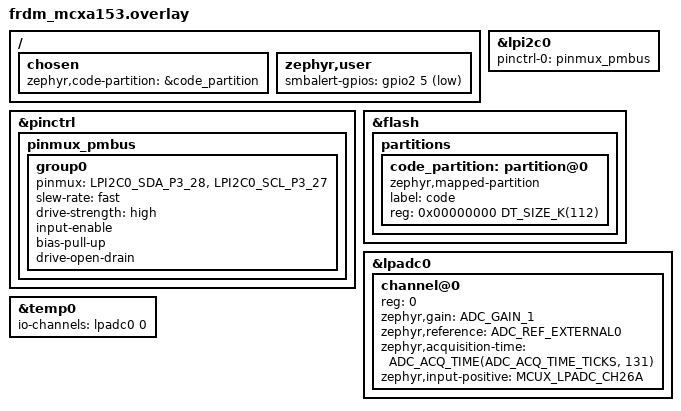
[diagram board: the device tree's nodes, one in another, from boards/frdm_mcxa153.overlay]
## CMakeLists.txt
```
# SPDX-License-Identifier: Apache-2.0
cmake_minimum_required(VERSION 3.20.0)

find_package(Zephyr REQUIRED HINTS $ENV{ZEPHYR_BASE})
project(pmbus_target)

set(PMBUS_LIB ${CMAKE_CURRENT_SOURCE_DIR}/../lib/pmbus)

target_include_directories(app PRIVATE ${PMBUS_LIB}/include)
target_sources(app PRIVATE
  ${PMBUS_LIB}/src/device.c
  ${PMBUS_LIB}/src/format.c
  ${PMBUS_LIB}/src/target.c
  src/main.c
  src/pmbus_i2c.c
  src/storage.c
  src/shell_cmds.c
)
```

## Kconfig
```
# SPDX-License-Identifier: Apache-2.0

mainmenu "FRDM-MCXA153 PMBus target"

config PMBUS_ADDRESS
	hex "PMBus target address (7-bit)"
	default 0x58
	range 0x08 0x77
	help
	  0x58 is the usual first PMBus address of a power supply; its FRU EEPROM would
	  sit at 0x50.

config PMBUS_UPDATE_PERIOD_MS
	int "Sensor and limit evaluation period (ms)"
	default 200

config PMBUS_SMBUS_TIMEOUT_MS
	int "SMBus target timeout (ms)"
	default 30
	help
	  If a transaction makes no progress for this long, the target interface resets
	  and the transaction is dropped. SMBus requires devices to reset between 25 ms
	  and 35 ms of SCL held low.

source "Kconfig.zephyr"
```

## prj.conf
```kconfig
# The PMBus target on LPI2C0.
CONFIG_I2C=y
CONFIG_I2C_TARGET=y

# Sensors: the P3T1755 on I3C0 and the die temperature through the ADC.
CONFIG_SENSOR=y
CONFIG_I3C=y
CONFIG_ADC=y

CONFIG_GPIO=y
CONFIG_HWINFO=y

# STORE_DEFAULT_ALL writes to the storage partition.
CONFIG_FLASH=y
CONFIG_FLASH_MAP=y
CONFIG_CRC=y

CONFIG_SHELL=y
CONFIG_LOG=y
CONFIG_LOG_MODE_MINIMAL=y
CONFIG_MAIN_STACK_SIZE=1536
```

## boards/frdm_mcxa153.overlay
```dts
/*
 * FRDM-MCXA153 as a PMBus target.
 *
 * SPDX-License-Identifier: Apache-2.0
 */

#include <zephyr/dt-bindings/adc/adc.h>
#include <zephyr/dt-bindings/adc/mcux-lpadc.h>
#include <zephyr/dt-bindings/gpio/gpio.h>

/ {
	chosen {
		zephyr,code-partition = &code_partition;
	};

	zephyr,user {
		/* SMBALERT#, open drain, on the mikroBUS INT pin (P2_5). */
		smbalert-gpios = <&gpio2 5 (GPIO_ACTIVE_LOW | GPIO_OPEN_DRAIN)>;
	};
};

/*
 * The PMBus pins: LPI2C0 on P3_27 (SCL) and P3_28 (SDA), the mikroBUS header J5 pins
 * 5 and 6. They are the only 5 V tolerant pins on the MCX A153, and the same pins
 * frdm-mcxa153-usb-i2c-hub uses, so two boards wire header to header.
 */
&pinctrl {
	pinmux_pmbus: pinmux_pmbus {
		group0 {
			pinmux = <LPI2C0_SDA_P3_28>,
				 <LPI2C0_SCL_P3_27>;
			slew-rate = "fast";
			drive-strength = "high";
			input-enable;
			bias-pull-up;
			drive-open-drain;
		};
	};
};

&lpi2c0 {
	pinctrl-0 = <&pinmux_pmbus>;
};

/* The board reserves the flash for MCUboot; this app runs without it. */
/delete-node/ &boot_partition;
/delete-node/ &slot0_partition;
/delete-node/ &slot1_partition;

&flash {
	partitions {
		code_partition: partition@0 {
			compatible = "zephyr,mapped-partition";
			label = "code";
			reg = <0x00000000 DT_SIZE_K(112)>;
		};
	};
};

/* The die temperature sensor, as samples/sensor/die_temp_polling sets it up. */
&lpadc0 {
	status = "okay";
	#address-cells = <1>;
	#size-cells = <0>;

	channel@0 {
		reg = <0>;
		zephyr,gain = "ADC_GAIN_1";
		zephyr,reference = "ADC_REF_EXTERNAL0";
		zephyr,acquisition-time = <ADC_ACQ_TIME(ADC_ACQ_TIME_TICKS, 131)>;
		zephyr,input-positive = <MCUX_LPADC_CH26A>;
	};
};

&temp0 {
	status = "okay";
	io-channels = <&lpadc0 0>;
};
```

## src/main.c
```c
/*
 * FRDM-MCXA153 PMBus target: a simulated 54 V to 12 V converter at
 * CONFIG_PMBUS_ADDRESS on LPI2C0, with its temperatures read from the on-board P3T1755
 * (READ_TEMPERATURE_1) and the MCU die (READ_TEMPERATURE_2).
 *
 * LEDs: green while the output is on and no status bit is set, red while any status
 * bit is set, blue on PMBus traffic.
 *
 * SPDX-License-Identifier: Apache-2.0
 */

#include <stdio.h>

#include <zephyr/device.h>
#include <zephyr/drivers/gpio.h>
#include <zephyr/drivers/hwinfo.h>
#include <zephyr/drivers/sensor.h>
#include <zephyr/kernel.h>
#include <zephyr/logging/log.h>

#include <pmbus/pmbus.h>

#include "app.h"

LOG_MODULE_REGISTER(main, LOG_LEVEL_INF);

struct pmbus_device pmbus_dev;
struct temp_override temp_override[2];

static const struct device *const temp_dev[2] = {
	DEVICE_DT_GET_OR_NULL(DT_ALIAS(ambient_temp0)),
	DEVICE_DT_GET_OR_NULL(DT_ALIAS(die_temp0)),
};
static const enum sensor_channel temp_chan[2] = {
	SENSOR_CHAN_AMBIENT_TEMP,
	SENSOR_CHAN_DIE_TEMP,
};

static const struct gpio_dt_spec led_green = GPIO_DT_SPEC_GET(DT_NODELABEL(green_led), gpios);
static const struct gpio_dt_spec led_red = GPIO_DT_SPEC_GET(DT_NODELABEL(red_led), gpios);
static const struct gpio_dt_spec led_blue = GPIO_DT_SPEC_GET(DT_NODELABEL(blue_led), gpios);

static bool read_temp(int i, int32_t *mc)
{
	struct sensor_value v;

	if (temp_override[i].active) {
		*mc = temp_override[i].mc;
		return true;
	}
	if (temp_dev[i] == NULL || !device_is_ready(temp_dev[i]) ||
	    sensor_sample_fetch(temp_dev[i]) != 0 ||
	    sensor_channel_get(temp_dev[i], temp_chan[i], &v) != 0) {
		return false;
	}
	*mc = v.val1 * 1000 + v.val2 / 1000;
	return true;
}

/* MFR_SERIAL: the first 8 bytes of the chip's unique ID, in hex. */
static void make_serial(char *buf, size_t len)
{
	uint8_t id[8];
	ssize_t n = hwinfo_get_device_id(id, sizeof(id));

	buf[0] = '\0';
	for (ssize_t i = 0; i < n && (size_t)(2 * i + 2) < len; i++) {
		snprintf(&buf[2 * i], 3, "%02X", id[i]);
	}
}

int main(void)
{
	char serial[17];
	struct pmbus_sensors s = {0};
	uint32_t last_transactions = 0;
	unsigned int key;
	int ret;

	gpio_pin_configure_dt(&led_green, GPIO_OUTPUT_INACTIVE);
	gpio_pin_configure_dt(&led_red, GPIO_OUTPUT_INACTIVE);
	gpio_pin_configure_dt(&led_blue, GPIO_OUTPUT_INACTIVE);

	make_serial(serial, sizeof(serial));
	pmbus_device_init(&pmbus_dev, CONFIG_PMBUS_ADDRESS, &storage_device_ops, NULL,
			  DT_NODE_HAS_PROP(DT_PATH(zephyr_user), smbalert_gpios), serial);
	if (storage_init() != 0) {
		LOG_ERR("storage partition unreadable; using defaults");
	}
	pmbus_device_load_stored(&pmbus_dev);

	s.temp1_valid = read_temp(0, &s.temp1_mc);
	s.temp2_valid = read_temp(1, &s.temp2_mc);
	LOG_INF("temperature 1 (P3T1755): %s, temperature 2 (die): %s",
		s.temp1_valid ? "ok" : "missing", s.temp2_valid ? "ok" : "missing");
	pmbus_device_update(&pmbus_dev, &s);

	ret = pmbus_i2c_start();
	if (ret != 0) {
		gpio_pin_set_dt(&led_red, 1);
		return ret;
	}

	while (true) {
		k_msleep(CONFIG_PMBUS_UPDATE_PERIOD_MS);

		s.temp1_valid = read_temp(0, &s.temp1_mc);
		s.temp2_valid = read_temp(1, &s.temp2_mc);

		key = irq_lock();
		pmbus_device_update(&pmbus_dev, &s);
		bool on = pmbus_dev.output_on;
		/* Being off, busy or not power-good alone is not a fault. */
		bool flagged = (pmbus_device_status_word(&pmbus_dev) &
				~(PMBUS_SB_OFF | PMBUS_SB_BUSY | PMBUS_SW_POWER_GOOD_N)) != 0;
		uint32_t transactions = pmbus_dev.target.n_transactions;
		irq_unlock(key);

		gpio_pin_set_dt(&led_green, on && !flagged);
		gpio_pin_set_dt(&led_red, flagged);
		gpio_pin_set_dt(&led_blue, transactions != last_transactions);
		last_transactions = transactions;
	}
	return 0;
}
```

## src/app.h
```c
/*
 * SPDX-License-Identifier: Apache-2.0
 */

#ifndef APP_H_
#define APP_H_

#include <stdbool.h>
#include <stdint.h>

#include <pmbus/device.h>

/* The one PMBus device. Thread code must hold irq_lock() while touching it. */
extern struct pmbus_device pmbus_dev;

/* Starts the I2C target on LPI2C0. */
int pmbus_i2c_start(void);
/* Drives SMBALERT#; safe in interrupt context. */
void pmbus_i2c_set_alert(bool asserted);
/* Counts of transactions, SMBus timeouts and interface resets. */
void pmbus_i2c_stats(uint32_t *timeouts);

/* Reads the stored config into RAM. Call before pmbus_device_load_stored(). */
int storage_init(void);
extern const struct pmbus_device_ops storage_device_ops;

/* Sensor overrides from the shell, for testing limits without a heat gun. */
struct temp_override {
	bool active;
	int32_t mc;
};
extern struct temp_override temp_override[2];

#endif /* APP_H_ */
```

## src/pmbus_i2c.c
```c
/*
 * Glue between Zephyr's I2C target API (LPI2C0) and the PMBus target engine.
 *
 * The Zephyr LPI2C driver reports every byte from its interrupt handler, which is what
 * the engine expects. This file adds what the driver lacks for SMBus:
 *  - a timeout: a transaction that makes no progress for CONFIG_PMBUS_SMBUS_TIMEOUT_MS
 *    resets the target interface, releasing SDA if a host vanished mid-read;
 *  - the Alert Response Address: while SMBALERT# is asserted, the LPI2C also answers
 *    0x0C (SCFGR1[SAEN]), and the engine replies with this device's address.
 *
 * SPDX-License-Identifier: Apache-2.0
 */

#include <zephyr/device.h>
#include <zephyr/drivers/gpio.h>
#include <zephyr/drivers/i2c.h>
#include <zephyr/kernel.h>
#include <zephyr/logging/log.h>

#include <soc.h>

#include <pmbus/pmbus.h>

#include "app.h"

LOG_MODULE_REGISTER(pmbus_i2c, LOG_LEVEL_INF);

#define I2C_NODE DT_NODELABEL(lpi2c0)

static const struct device *const i2c_dev = DEVICE_DT_GET(I2C_NODE);
static LPI2C_Type *const lpi2c = (LPI2C_Type *)DT_REG_ADDR(I2C_NODE);

#define USER_NODE DT_PATH(zephyr_user)
static const struct gpio_dt_spec alert_gpio = GPIO_DT_SPEC_GET_OR(USER_NODE, smbalert_gpios, {0});

static struct i2c_target_config target_cfg;
static uint32_t n_timeouts;
static atomic_t alert_wanted;

static void timeout_expired(struct k_timer *timer);
static void reset_work_fn(struct k_work *work);
static void ara_work_fn(struct k_work *work);

static K_TIMER_DEFINE(timeout_timer, timeout_expired, NULL);
static K_WORK_DEFINE(reset_work, reset_work_fn);
static K_WORK_DELAYABLE_DEFINE(ara_work, ara_work_fn);

static inline void progress(void)
{
	k_timer_start(&timeout_timer, K_MSEC(CONFIG_PMBUS_SMBUS_TIMEOUT_MS), K_NO_WAIT);
}

static int on_write_requested(struct i2c_target_config *cfg)
{
	ARG_UNUSED(cfg);
	progress();
	pmbus_target_write_start(&pmbus_dev.target);
	return 0;
}

static int on_write_received(struct i2c_target_config *cfg, uint8_t val)
{
	ARG_UNUSED(cfg);
	progress();
	return pmbus_target_write_byte(&pmbus_dev.target, val) ? 0 : -EIO;
}

/*
 * Says whether this read is to the Alert Response Address rather than our own. The driver
 * has already read SASR; RADDR keeps the matched address (8-bit form) unless ANV says it
 * is stale, in which case fall back on context: a read with no command written first,
 * while alerting, is taken as the alert response.
 */
static bool is_alert_response_read(void)
{
	uint32_t sasr = lpi2c->SASR;

	if (!(sasr & LPI2C_SASR_ANV_MASK)) {
		return ((sasr & LPI2C_SASR_RADDR_MASK) >> 1) == SMBUS_ALERT_RESPONSE_ADDR;
	}
	return atomic_get(&alert_wanted) && pmbus_dev.target.rx_len == 0;
}

static int on_read_requested(struct i2c_target_config *cfg, uint8_t *val)
{
	ARG_UNUSED(cfg);
	progress();
	if (is_alert_response_read()) {
		*val = pmbus_target_ara_start(&pmbus_dev.target);
	} else {
		*val = pmbus_target_read_start(&pmbus_dev.target);
	}
	return 0;
}

static int on_read_processed(struct i2c_target_config *cfg, uint8_t *val)
{
	ARG_UNUSED(cfg);
	progress();
	*val = pmbus_target_read_byte(&pmbus_dev.target);
	return 0;
}

static int on_stop(struct i2c_target_config *cfg)
{
	ARG_UNUSED(cfg);
	k_timer_stop(&timeout_timer);
	pmbus_target_stop(&pmbus_dev.target);
	return 0;
}

static const struct i2c_target_callbacks callbacks = {
	.write_requested = on_write_requested,
	.write_received = on_write_received,
	.read_requested = on_read_requested,
	.read_processed = on_read_processed,
	.stop = on_stop,
};

/* SCFGR1 may only change while the target is disabled. */
static void set_alert_response(bool enable)
{
	uint32_t scr = lpi2c->SCR;

	lpi2c->SCR = scr & ~LPI2C_SCR_SEN_MASK;
	if (enable) {
		lpi2c->SCFGR1 |= LPI2C_SCFGR1_SAEN_MASK;
	} else {
		lpi2c->SCFGR1 &= ~LPI2C_SCFGR1_SAEN_MASK;
	}
	lpi2c->SCR = scr;
}

static void ara_work_fn(struct k_work *work)
{
	/* Wait for a quiet bus, so the switch can't cut into a transaction. */
	if (lpi2c->SSR & (LPI2C_SSR_SBF_MASK | LPI2C_SSR_BBF_MASK)) {
		k_work_reschedule(k_work_delayable_from_work(work), K_MSEC(1));
		return;
	}
	set_alert_response(atomic_get(&alert_wanted) != 0);
}

void pmbus_i2c_set_alert(bool asserted)
{
	if (alert_gpio.port != NULL) {
		gpio_pin_set_dt(&alert_gpio, asserted);
	}
	atomic_set(&alert_wanted, asserted);
	k_work_reschedule(&ara_work, K_NO_WAIT);
}

static int target_register(void)
{
	int ret = i2c_target_register(i2c_dev, &target_cfg);

	if (ret == 0 && atomic_get(&alert_wanted)) {
		set_alert_response(true);
	}
	return ret;
}

static void reset_work_fn(struct k_work *work)
{
	unsigned int key;

	ARG_UNUSED(work);
	LOG_WRN("SMBus timeout, resetting the target interface");
	key = irq_lock();
	pmbus_target_abort(&pmbus_dev.target);
	irq_unlock(key);
	i2c_target_unregister(i2c_dev, &target_cfg);
	if (target_register() != 0) {
		LOG_ERR("re-registering the I2C target failed");
	}
}

static void timeout_expired(struct k_timer *timer)
{
	ARG_UNUSED(timer);
	n_timeouts++;
	k_work_submit(&reset_work);
}

void pmbus_i2c_stats(uint32_t *timeouts)
{
	*timeouts = n_timeouts;
}

int pmbus_i2c_start(void)
{
	int ret;

	if (!device_is_ready(i2c_dev)) {
		LOG_ERR("LPI2C0 not ready");
		return -ENODEV;
	}
	if (alert_gpio.port != NULL) {
		ret = gpio_pin_configure_dt(&alert_gpio, GPIO_OUTPUT_INACTIVE);
		if (ret != 0) {
			LOG_ERR("SMBALERT# pin: %d", ret);
			return ret;
		}
	}

	target_cfg.address = CONFIG_PMBUS_ADDRESS;
	target_cfg.callbacks = &callbacks;
	ret = target_register();
	if (ret != 0) {
		LOG_ERR("i2c_target_register: %d", ret);
		return ret;
	}
	LOG_INF("PMBus target at 0x%02x", CONFIG_PMBUS_ADDRESS);
	return 0;
}
```

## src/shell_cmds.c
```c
/*
 * Shell commands on the debug UART for watching the device and steering the
 * simulation by hand.
 *
 * SPDX-License-Identifier: Apache-2.0
 */

#include <stdlib.h>
#include <string.h>

#include <zephyr/kernel.h>
#include <zephyr/shell/shell.h>

#include <pmbus/pmbus.h>

#include "app.h"

/* Prints a milli-unit value as a decimal with three places. */
#define MILLI(v) ((v) < 0 ? "-" : ""), abs((v) / 1000), abs((v) % 1000)

static int cmd_status(const struct shell *sh, size_t argc, char **argv)
{
	struct pmbus_device d;
	uint32_t timeouts;
	unsigned int key;

	ARG_UNUSED(argc);
	ARG_UNUSED(argv);

	key = irq_lock();
	d = pmbus_dev;
	irq_unlock(key);
	pmbus_i2c_stats(&timeouts);

	shell_print(sh, "address 0x%02x, output %s%s", d.target.addr, d.output_on ? "on" : "off",
		    d.fault_off ? " (latched off by a fault)" : "");
	shell_print(sh, "VIN  %s%d.%03d V   IIN  %s%d.%03d A   PIN  %s%d.%03d W", MILLI(d.vin_mv),
		    MILLI(d.iin_ma), MILLI(d.pin_mw));
	shell_print(sh, "VOUT %s%d.%03d V   IOUT %s%d.%03d A   POUT %s%d.%03d W",
		    MILLI(d.vout_mv), MILLI(d.iout_ma), MILLI(d.pout_mw));
	shell_print(sh, "TEMP1 %s%s%d.%03d C   TEMP2 %s%s%d.%03d C",
		    d.sensors.temp1_valid ? "" : "(missing) ", MILLI(d.sensors.temp1_mc),
		    d.sensors.temp2_valid ? "" : "(missing) ", MILLI(d.sensors.temp2_mc));
	shell_print(sh, "STATUS_WORD 0x%04x  VOUT 0x%02x  IOUT 0x%02x  INPUT 0x%02x  "
		    "TEMPERATURE 0x%02x  CML 0x%02x",
		    pmbus_device_status_word(&d), d.status_vout, d.status_iout, d.status_input,
		    d.status_temp, d.status_cml);
	shell_print(sh, "SMBALERT# %s, transactions %u, PEC errors %u, aborts %u, timeouts %u",
		    d.alert_pending ? "asserted" : "released", d.target.n_transactions,
		    d.target.n_pec_errors, d.target.n_aborts, timeouts);
	return 0;
}

static int cmd_load(const struct shell *sh, size_t argc, char **argv)
{
	unsigned int key = irq_lock();

	ARG_UNUSED(argc);
	pmbus_dev.sim.load_ma = (int32_t)strtol(argv[1], NULL, 0);
	pmbus_device_update(&pmbus_dev, NULL);
	irq_unlock(key);
	shell_print(sh, "load %s mA", argv[1]);
	return 0;
}

static int cmd_vin(const struct shell *sh, size_t argc, char **argv)
{
	unsigned int key = irq_lock();

	ARG_UNUSED(argc);
	pmbus_dev.sim.vin_mv = (int32_t)strtol(argv[1], NULL, 0);
	pmbus_device_update(&pmbus_dev, NULL);
	irq_unlock(key);
	shell_print(sh, "VIN %s mV", argv[1]);
	return 0;
}

static int cmd_temp(const struct shell *sh, size_t argc, char **argv)
{
	long i = strtol(argv[1], NULL, 0);

	ARG_UNUSED(argc);
	if (i != 1 && i != 2) {
		shell_error(sh, "sensor is 1 or 2");
		return -EINVAL;
	}
	if (strcmp(argv[2], "off") == 0) {
		temp_override[i - 1].active = false;
		shell_print(sh, "temperature %ld: real sensor", i);
	} else {
		temp_override[i - 1].mc = (int32_t)strtol(argv[2], NULL, 0);
		temp_override[i - 1].active = true;
		shell_print(sh, "temperature %ld: %s m°C until 'pmbus temp %ld off'", i, argv[2],
			    i);
	}
	return 0;
}

static int cmd_control(const struct shell *sh, size_t argc, char **argv)
{
	unsigned int key = irq_lock();

	ARG_UNUSED(argc);
	pmbus_device_set_control_pin(&pmbus_dev, strtol(argv[1], NULL, 0) != 0);
	irq_unlock(key);
	shell_print(sh, "CONTROL %s", argv[1]);
	return 0;
}

static int cmd_clear(const struct shell *sh, size_t argc, char **argv)
{
	unsigned int key = irq_lock();

	ARG_UNUSED(argc);
	ARG_UNUSED(argv);
	pmbus_device_clear_faults(&pmbus_dev);
	irq_unlock(key);
	shell_print(sh, "faults cleared");
	return 0;
}

SHELL_STATIC_SUBCMD_SET_CREATE(pmbus_cmds,
	SHELL_CMD(status, NULL, "Telemetry, status registers and counters", cmd_status),
	SHELL_CMD_ARG(load, NULL, "<mA>  Simulated load current", cmd_load, 2, 0),
	SHELL_CMD_ARG(vin, NULL, "<mV>  Simulated input voltage", cmd_vin, 2, 0),
	SHELL_CMD_ARG(temp, NULL, "<1|2> <m°C|off>  Override a temperature sensor",
		      cmd_temp, 3, 0),
	SHELL_CMD_ARG(control, NULL, "<0|1>  The CONTROL input (see ON_OFF_CONFIG)",
		      cmd_control, 2, 0),
	SHELL_CMD(clear, NULL, "CLEAR_FAULTS", cmd_clear),
	SHELL_SUBCMD_SET_END);

SHELL_CMD_REGISTER(pmbus, &pmbus_cmds, "PMBus target", NULL);
```

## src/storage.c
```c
/*
 * STORE_DEFAULT_ALL and RESTORE_DEFAULT_ALL, backed by the storage partition.
 *
 * One record lives at the start of the partition. A RAM copy answers
 * RESTORE_DEFAULT_ALL straight from the I2C interrupt; a work item does the flash
 * erase and write that STORE_DEFAULT_ALL asks for.
 *
 * SPDX-License-Identifier: Apache-2.0
 */

#include <string.h>

#include <zephyr/kernel.h>
#include <zephyr/logging/log.h>
#include <zephyr/storage/flash_map.h>
#include <zephyr/sys/crc.h>

#include "app.h"

LOG_MODULE_REGISTER(storage, LOG_LEVEL_INF);

#define STORAGE_ID   PARTITION_ID(storage_partition)
#define RECORD_MAGIC 0x504d4231 /* "PMB1" */

struct record {
	uint32_t magic;
	struct pmbus_device_config cfg;
	uint32_t crc;
};

/* Flash writes go in 16-byte phrases. */
#define RECORD_SIZE ROUND_UP(sizeof(struct record), 16)

static union {
	struct record r;
	uint8_t raw[RECORD_SIZE];
} __aligned(4) shadow, pending;

static bool shadow_valid;

static uint32_t record_crc(const struct record *r)
{
	return crc32_ieee((const uint8_t *)r, offsetof(struct record, crc));
}

int storage_init(void)
{
	const struct flash_area *fa;
	int ret = flash_area_open(STORAGE_ID, &fa);

	if (ret != 0) {
		return ret;
	}
	ret = flash_area_read(fa, 0, shadow.raw, sizeof(shadow.raw));
	flash_area_close(fa);
	if (ret != 0) {
		return ret;
	}
	shadow_valid = shadow.r.magic == RECORD_MAGIC && shadow.r.crc == record_crc(&shadow.r);
	LOG_INF("stored config: %s", shadow_valid ? "found" : "none");
	return 0;
}

static void store_work_fn(struct k_work *work)
{
	const struct flash_area *fa;
	unsigned int key;
	bool ok = false;

	ARG_UNUSED(work);

	if (flash_area_open(STORAGE_ID, &fa) == 0) {
		ok = flash_area_flatten(fa, 0, fa->fa_size) == 0 &&
		     flash_area_write(fa, 0, pending.raw, sizeof(pending.raw)) == 0;
		flash_area_close(fa);
	}
	key = irq_lock();
	if (ok) {
		shadow = pending;
		shadow_valid = true;
	}
	pmbus_device_store_done(&pmbus_dev, ok);
	irq_unlock(key);
	LOG_INF("STORE_DEFAULT_ALL %s", ok ? "done" : "failed");
}

static K_WORK_DEFINE(store_work, store_work_fn);

static void set_alert(void *ctx, bool asserted)
{
	ARG_UNUSED(ctx);
	pmbus_i2c_set_alert(asserted);
}

/* Called from the I2C interrupt. */
static void store(void *ctx, const struct pmbus_device_config *cfg)
{
	ARG_UNUSED(ctx);
	memset(&pending, 0xFF, sizeof(pending));
	pending.r.magic = RECORD_MAGIC;
	pending.r.cfg = *cfg;
	pending.r.crc = record_crc(&pending.r);
	k_work_submit(&store_work);
}

static bool restore(void *ctx, struct pmbus_device_config *cfg)
{
	ARG_UNUSED(ctx);
	if (!shadow_valid) {
		return false;
	}
	*cfg = shadow.r.cfg;
	return true;
}

const struct pmbus_device_ops storage_device_ops = {
	.set_alert = set_alert,
	.store = store,
	.restore = restore,
};
```
